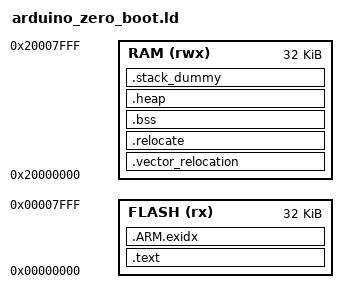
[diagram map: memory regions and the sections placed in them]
/**
 * \file
 *
 * \brief Linker script for running in internal FLASH on the SAMD21G18A
 *
 * Copyright (c) 2014-2015 Atmel Corporation. All rights reserved.
 *
 * \asf_license_start
 *
 * \page License
 *
 * Redistribution and use in source and binary forms, with or without
 * modification, are permitted provided that the following conditions are met:
 *
 * 1. Redistributions of source code must retain the above copyright notice,
 *    this list of conditions and the following disclaimer.
 *
 * 2. Redistributions in binary form must reproduce the above copyright notice,
 *    this list of conditions and the following disclaimer in the documentation
 *    and/or other materials provided with the distribution.
 *
 * 3. The name of Atmel may not be used to endorse or promote products derived
 *    from this software without specific prior written permission.
 *
 * 4. This software may only be redistributed and used in connection with an
 *    Atmel microcontroller product.
 *
 * THIS SOFTWARE IS PROVIDED BY ATMEL "AS IS" AND ANY EXPRESS OR IMPLIED
 * WARRANTIES, INCLUDING, BUT NOT LIMITED TO, THE IMPLIED WARRANTIES OF
 * MERCHANTABILITY, FITNESS FOR A PARTICULAR PURPOSE AND NON-INFRINGEMENT ARE
 * EXPRESSLY AND SPECIFICALLY DISCLAIMED. IN NO EVENT SHALL ATMEL BE LIABLE FOR
 * ANY DIRECT, INDIRECT, INCIDENTAL, SPECIAL, EXEMPLARY, OR CONSEQUENTIAL
 * DAMAGES (INCLUDING, BUT NOT LIMITED TO, PROCUREMENT OF SUBSTITUTE GOODS
 * OR SERVICES; LOSS OF USE, DATA, OR PROFITS; OR BUSINESS INTERRUPTION)
 * HOWEVER CAUSED AND ON ANY THEORY OF LIABILITY, WHETHER IN CONTRACT,
 * STRICT LIABILITY, OR TORT (INCLUDING NEGLIGENCE OR OTHERWISE) ARISING IN
 * ANY WAY OUT OF THE USE OF THIS SOFTWARE, EVEN IF ADVISED OF THE
 * POSSIBILITY OF SUCH DAMAGE.
 *
 * \asf_license_stop
 *
 */


OUTPUT_FORMAT("elf32-littlearm", "elf32-littlearm", "elf32-littlearm")
OUTPUT_ARCH(arm)
SEARCH_DIR(.)

/* Memory Spaces Definitions */
MEMORY
{
  FLASH    (rx)  : ORIGIN = 0x00000000, LENGTH = 0x00008000
  RAM      (rwx) : ORIGIN = 0x20000000, LENGTH = 0x00008000
}

/* Generate a link error if heap and stack don't fit into RAM */
_Min_Heap_Size = 0x200;      /* required amount of heap  */
_Min_Stack_Size = 0x200; /* required amount of stack */

/* The stack size used by the application. NOTE: you need to adjust according to your application. */
STACK_SIZE = DEFINED(STACK_SIZE) ? STACK_SIZE : DEFINED(__stack_size__) ? __stack_size__ : 0x400;

ENTRY(Reset_Handler)

/* Section Definitions */
SECTIONS
{
    .text :
    {
        . = ALIGN(4);
        _sfixed = .;
        __isr_vector_start = .;
        KEEP(*(.vectors .vectors.*))
        __isr_vector_end = .;

        *(.text .text.* .gnu.linkonce.t.*)
        *(.glue_7t) *(.glue_7)
        *(.rodata .rodata* .gnu.linkonce.r.*)
        *(.ARM.extab* .gnu.linkonce.armextab.*)

        /* Support C constructors, and C destructors in both user code
           and the C library. This also provides support for C++ code. */
        . = ALIGN(4);
        KEEP(*(.init))
        . = ALIGN(4);
        __preinit_array_start = .;
        KEEP (*(.preinit_array))
        __preinit_array_end = .;

        . = ALIGN(4);
        __init_array_start = .;
        KEEP (*(SORT(.init_array.*)))
        KEEP (*(.init_array))
        __init_array_end = .;

        . = ALIGN(4);
        KEEP (*crtbegin.o(.ctors))
        KEEP (*(EXCLUDE_FILE (*crtend.o) .ctors))
        KEEP (*(SORT(.ctors.*)))
        KEEP (*crtend.o(.ctors))

        . = ALIGN(4);
        KEEP(*(.fini))

        . = ALIGN(4);
        __fini_array_start = .;
        KEEP (*(.fini_array))
        KEEP (*(SORT(.fini_array.*)))
        __fini_array_end = .;

        KEEP (*crtbegin.o(.dtors))
        KEEP (*(EXCLUDE_FILE (*crtend.o) .dtors))
        KEEP (*(SORT(.dtors.*)))
        KEEP (*crtend.o(.dtors))

        . = ALIGN(4);
        _efixed = .;            /* End of text section */
    } > FLASH

    /* .ARM.exidx is sorted, so has to go in its own output section.  */
    PROVIDE_HIDDEN (__exidx_start = .);
    .ARM.exidx :
    {
      *(.ARM.exidx* .gnu.linkonce.armexidx.*)
    } > FLASH
    PROVIDE_HIDDEN (__exidx_end = .);

    . = ALIGN(4);
    _etext = .;

    .vector_relocation :
    {
        . = ALIGN(4);
        __vector_tbl_reloc__ = .;
        . = . + (__isr_vector_end - __isr_vector_start);
        . = ALIGN(4);
    } > RAM

    .relocate : AT (_etext)
    {
        . = ALIGN(4);
        _srelocate = .;
        *(.data .data.*);
        . = ALIGN(4);
        _erelocate = .;
    } > RAM

    /* .bss section which is used for uninitialized data */
    .bss (NOLOAD) :
    {
        . = ALIGN(4);
	__bss_start__ = . ;
        _sbss = . ;
        _szero = .;
        *(.bss .bss.*)
        *(COMMON)
        . = ALIGN(4);
	__bss_end__ = . ;
        _ebss = . ;
        _ezero = .;
    } > RAM

    /* Heap starts after BSS */
    __HeapBase = .;

  /* User_heap_stack section, used to check that there is enough RAM left */
  .heap :
  {
    . = ALIGN(4);
    PROVIDE ( _user_heap_start = . );
    . = . + _Min_Heap_Size;
    . = ALIGN(4);
  } > RAM 


    /* .stack_dummy section doesn't contains any symbols. It is only
     * used for linker to calculate size of stack sections, and assign
     * values to stack symbols later */
    .stack_dummy (COPY):
    {
        . = . + STACK_SIZE;
        *(.stack*)
    } > RAM

    /* Set stack top to end of RAM, and stack limit move down by
     * size of stack_dummy section */
    __StackTop = ORIGIN(RAM) + LENGTH(RAM);
    __StackLimit = __StackTop - SIZEOF(.stack_dummy);
    PROVIDE(__stack = __StackTop);

    /* Top of head is the bottom of the stack */
  _user_heap_end = __StackLimit;
  __HeapLimit = __StackLimit;


    /* Check if data + heap + stack exceeds RAM limit */
    ASSERT(__HeapBase <= __HeapLimit, "region RAM overflowed with stack")

}
